# CY8C5568AXI_060 register map
File version: 0.1
CY8C55
Registers are 8-bit, read-write, no defined reset value unless marked. A register's access mark holds for its fields unless they carry their own. Offsets are from the block's base; lines under a group give offsets from that group; [hi:lo] are bit positions; {n}, {i} and the like mark numbered series; 'fields as' and 'values as' point back to an identical list; <NAME> marks a mode.

## Memory map
0x400043AA ADCSharp size 0x17E0
0x40006421 UART_XBee size 0x4B — UART
0x40006424 UART_Asser size 0x141 — UART
0x40006426 PWM_ServoQueue size 0x151
0x4000650A Timer_Fin size 0x92
0x40006524 PWM_ServoBrasGauche size 0x72
0x40006526 PWM_ServoBrasDroit size 0x72

## UART_XBee — UART
Base 0x40006421
0x00 RX_UART_XBee_RX_ADDRESS1 — RX Address1 Register
0x10 RX_UART_XBee_RX_ADDRESS2 — RX Address2 Register
0x20 RX_UART_XBee_RX_DATA — RX Data Register
0x2A TX_UART_XBee_TX_DATA — TX Data Register
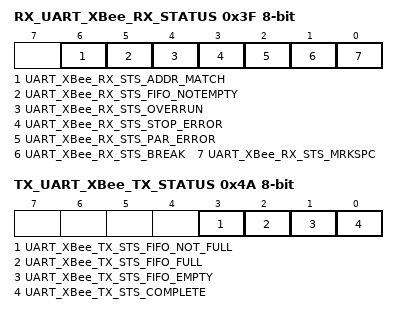
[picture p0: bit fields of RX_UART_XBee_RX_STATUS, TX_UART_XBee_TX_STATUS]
0x3F RX_UART_XBee_RX_STATUS — RX status register
  [6] UART_XBee_RX_STS_ADDR_MATCH ro, [5] UART_XBee_RX_STS_FIFO_NOTEMPTY ro, [4] UART_XBee_RX_STS_OVERRUN ro, [3] UART_XBee_RX_STS_STOP_ERROR ro, [2] UART_XBee_RX_STS_PAR_ERROR ro, [1] UART_XBee_RX_STS_BREAK ro, [0] UART_XBee_RX_STS_MRKSPC ro
0x4A TX_UART_XBee_TX_STATUS — TX status register
  [3] UART_XBee_TX_STS_FIFO_NOT_FULL ro, [2] UART_XBee_TX_STS_FIFO_FULL ro, [1] UART_XBee_TX_STS_FIFO_EMPTY ro, [0] UART_XBee_TX_STS_COMPLETE ro

## UART_Asser — UART
Base 0x40006424
0x00 RX_UART_Asser_RX_ADDRESS1 — RX Address1 Register
0x10 RX_UART_Asser_RX_ADDRESS2 — RX Address2 Register
0x1F TX_UART_Asser_TX_DATA — TX Data Register
0x20 RX_UART_Asser_RX_DATA — RX Data Register
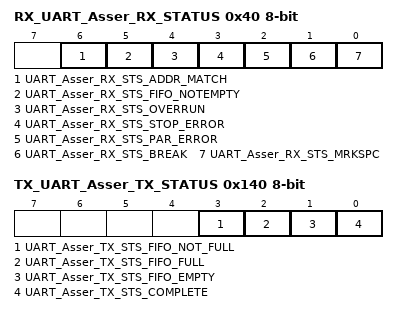
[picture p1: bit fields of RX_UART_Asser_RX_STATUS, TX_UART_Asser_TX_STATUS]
0x40 RX_UART_Asser_RX_STATUS — RX status register
  [6] UART_Asser_RX_STS_ADDR_MATCH ro, [5] UART_Asser_RX_STS_FIFO_NOTEMPTY ro, [4] UART_Asser_RX_STS_OVERRUN ro, [3] UART_Asser_RX_STS_STOP_ERROR ro, [2] UART_Asser_RX_STS_PAR_ERROR ro, [1] UART_Asser_RX_STS_BREAK ro, [0] UART_Asser_RX_STS_MRKSPC ro
0x140 TX_UART_Asser_TX_STATUS — TX status register
  [3] UART_Asser_TX_STS_FIFO_NOT_FULL ro, [2] UART_Asser_TX_STS_FIFO_FULL ro, [1] UART_Asser_TX_STS_FIFO_EMPTY ro, [0] UART_Asser_TX_STS_COMPLETE ro

## Timer_Fin
Base 0x4000650A
0x00 Timer_Fin_COUNTER 16-bit — UDB.A0 - Current Down Counter Value
0x20 Timer_Fin_PERIOD 16-bit — UDB.D0 - Assigned Period
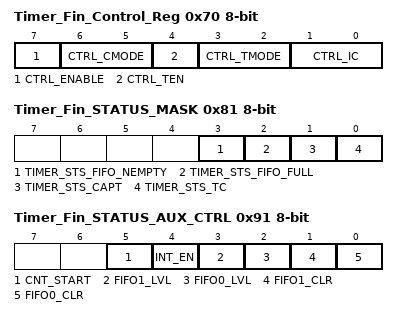
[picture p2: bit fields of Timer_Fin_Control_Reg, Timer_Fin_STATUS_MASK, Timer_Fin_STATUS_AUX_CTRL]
0x70 Timer_Fin_Control_Reg — UDB Control Register - Assigned Control Register Value
  [7] CTRL_ENABLE — Enable the Timer
  [6:5] CTRL_CMODE — Capture Mode
  [4] CTRL_TEN — Trigger Enable Bit
  [3:2] CTRL_TMODE — Trigger Mode
  [1:0] CTRL_IC — Interrupt Count
0x81 Timer_Fin_STATUS_MASK — UDB Status bits Interrupt Mask Enable Register
  [3] TIMER_STS_FIFO_NEMPTY ro — FIFO Empty status
  [2] TIMER_STS_FIFO_FULL ro — FIFO Full Status
  [1] TIMER_STS_CAPT ro — Enables the Interrupt on Capture
  [0] TIMER_STS_TC ro — Enables the Interrupt on TC
0x91 Timer_Fin_STATUS_AUX_CTRL — UDB Auxilliary Control Register
  [5] CNT_START — FIFO0 clear
    0=E_CNT_START0 (Disable counter); 1=E_CNT_START1 (Enable counter)
  [4] INT_EN
    0=E_INT_EN0 (Interrupt disabled); 1=E_INT_EN1 (Interrupt enabled)
  [3] FIFO1_LVL — FIFO level
    0=E_FIFO_LVL_0 (FIFO LVL: input mode: FIFO not full; output mode: FIFO not empty); 1=E_FIFO_LVL_1 (FIFO LVL: input mode: FIFO at least 1/2 empty; output mode: FIFO at least 1/2 full)
  [2] FIFO0_LVL — FIFO level
    values as FIFO1_LVL
  [1] FIFO1_CLR — FIFO1 clear
    0=E_FIFO_CLR_0 (Normal FIFO operation); 1=E_FIFO_CLR_1 (Clear FIFO state)
  [0] FIFO0_CLR — FIFO0 clear
    values as FIFO1_CLR

## PWM_ServoBrasDroit
Base 0x40006526
0x00 PWM_ServoBrasDroit_COMPARE_Reg 16-bit — UDB.D0 - Assigned Compare Value
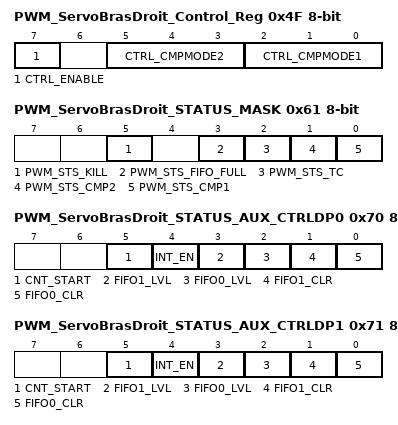
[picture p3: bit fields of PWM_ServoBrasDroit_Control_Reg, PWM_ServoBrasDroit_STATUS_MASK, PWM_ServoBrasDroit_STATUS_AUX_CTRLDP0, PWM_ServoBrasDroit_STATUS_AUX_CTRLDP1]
0x4F PWM_ServoBrasDroit_Control_Reg — UDB Control Register - Assigned Control Register Value
  [7] CTRL_ENABLE — Enable the PWM
  [5:3] CTRL_CMPMODE2 — Compare mode 2
  [2:0] CTRL_CMPMODE1 — Compare mode 1
0x61 PWM_ServoBrasDroit_STATUS_MASK — UDB Status bits Interrupt Mask Enable Register
  [5] PWM_STS_KILL ro — Enables the Interrupt on Kill
  [3] PWM_STS_FIFO_FULL ro — FIFO Full Status Mask
  [2] PWM_STS_TC ro — Enables the Interrupt on Terminal Count
  [1] PWM_STS_CMP2 ro — Enables the Interrupt on Compare 2
  [0] PWM_STS_CMP1 ro — Enables the Interrupt on Compare 1
0x70 PWM_ServoBrasDroit_STATUS_AUX_CTRLDP0 — UDB Auxilliary Control Register
  [5] CNT_START — FIFO0 clear
    0=E_CNT_START0 (Disable counter); 1=E_CNT_START1 (Enable counter)
  [4] INT_EN
    0=E_INT_EN0 (Interrupt disabled); 1=E_INT_EN1 (Interrupt enabled)
  [3] FIFO1_LVL — FIFO level
    0=E_FIFO_LVL_0 (FIFO LVL: input mode: FIFO not full; output mode: FIFO not empty); 1=E_FIFO_LVL_1 (FIFO LVL: input mode: FIFO at least 1/2 empty; output mode: FIFO at least 1/2 full)
  [2] FIFO0_LVL — FIFO level
    values as FIFO1_LVL
  [1] FIFO1_CLR — FIFO1 clear
    0=E_FIFO_CLR_0 (Normal FIFO operation); 1=E_FIFO_CLR_1 (Clear FIFO state)
  [0] FIFO0_CLR — FIFO0 clear
    values as FIFO1_CLR
0x71 PWM_ServoBrasDroit_STATUS_AUX_CTRLDP1 — UDB Auxilliary Control Register
  fields as PWM_ServoBrasDroit_STATUS_AUX_CTRLDP0

## PWM_ServoBrasGauche
Base 0x40006524
Registers as PWM_ServoBrasDroit (with PWM_ServoBrasDroit read as PWM_ServoBrasGauche), without PWM_ServoBrasDroit_Control_Reg; these are added or differ:
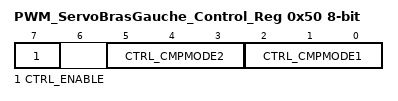
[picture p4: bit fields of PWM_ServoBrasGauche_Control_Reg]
0x50 PWM_ServoBrasGauche_Control_Reg — UDB Control Register - Assigned Control Register Value
  [7] CTRL_ENABLE — Enable the PWM
  [5:3] CTRL_CMPMODE2 — Compare mode 2
  [2:0] CTRL_CMPMODE1 — Compare mode 1

## PWM_ServoQueue
Base 0x40006426
Registers as PWM_ServoBrasDroit (with PWM_ServoBrasDroit read as PWM_ServoQueue), without PWM_ServoBrasDroit_Control_Reg; these are added or differ:
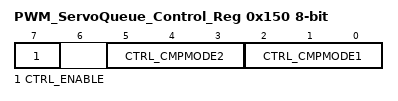
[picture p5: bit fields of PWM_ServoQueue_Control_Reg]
0x150 PWM_ServoQueue_Control_Reg — UDB Control Register - Assigned Control Register Value
  [7] CTRL_ENABLE — Enable the PWM
  [5:3] CTRL_CMPMODE2 — Compare mode 2
  [2:0] CTRL_CMPMODE1 — Compare mode 1
